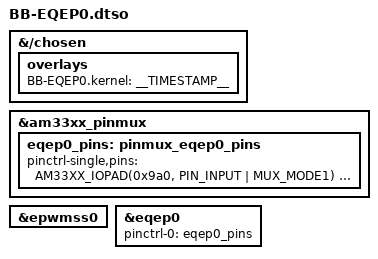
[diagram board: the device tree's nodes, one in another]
// SPDX-License-Identifier: GPL-2.0-only
/*
 * Copyright (C) 2025 Robert Nelson <robertcnelson@gmail.com>
 */

/dts-v1/;
/plugin/;

#include <dt-bindings/pinctrl/am33xx.h>

/*
 * Helper to show loaded overlays under: /proc/device-tree/chosen/overlays/
 */
&{/chosen} {
	overlays {
		BB-EQEP0.kernel = __TIMESTAMP__;
	};
};

&am33xx_pinmux {
	eqep0_pins: pinmux_eqep0_pins {
		pinctrl-single,pins = <
			AM33XX_IOPAD(0x9a0, PIN_INPUT | MUX_MODE1) /* (B12) mcasp0_aclkr.eQEP0A_in */
			AM33XX_IOPAD(0x9a4, PIN_INPUT | MUX_MODE1) /* (C13) mcasp0_fsr.eQEP0B_in */
			AM33XX_IOPAD(0x9a8, PIN_INPUT | MUX_MODE1) /* (D13) mcasp0_axr1.eQEP0_index */
			AM33XX_IOPAD(0x9ac, PIN_INPUT | MUX_MODE1) /* (A14) mcasp0_ahclkx.eQEP0_strobe */
		>;
	};
};

&epwmss0 {
	status = "okay";
};

&eqep0 {
	status = "okay";
	pinctrl-names = "default";
	pinctrl-0 = <&eqep0_pins>;
};
